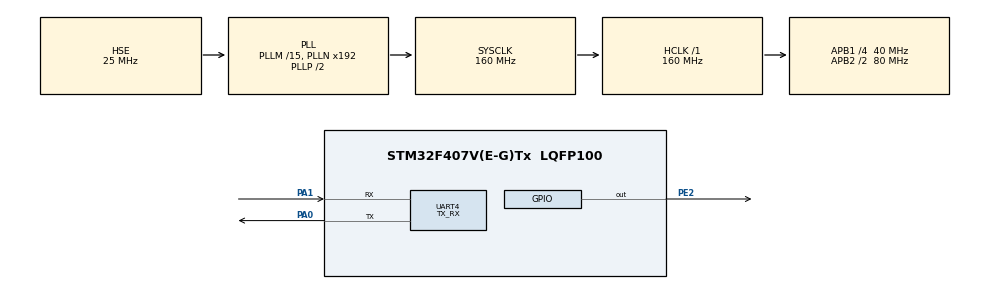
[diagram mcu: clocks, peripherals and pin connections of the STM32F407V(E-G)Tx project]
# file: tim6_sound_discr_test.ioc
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Dma.Request0=TIM6_UP
Dma.TIM6_UP.0.Direction=DMA_MEMORY_TO_PERIPH
Dma.TIM6_UP.0.FIFOMode=DMA_FIFOMODE_ENABLE
Dma.TIM6_UP.0.FIFOThreshold=DMA_FIFO_THRESHOLD_FULL
Dma.TIM6_UP.0.Instance=DMA1_Stream1
Dma.TIM6_UP.0.MemBurst=DMA_MBURST_SINGLE
Dma.TIM6_UP.0.MemDataAlignment=DMA_MDATAALIGN_HALFWORD
Dma.TIM6_UP.0.MemInc=DMA_MINC_ENABLE
Dma.TIM6_UP.0.Mode=DMA_NORMAL
Dma.TIM6_UP.0.PeriphBurst=DMA_PBURST_SINGLE
Dma.TIM6_UP.0.PeriphDataAlignment=DMA_PDATAALIGN_HALFWORD
Dma.TIM6_UP.0.PeriphInc=DMA_PINC_DISABLE
Dma.TIM6_UP.0.Priority=DMA_PRIORITY_LOW
Mcu.Family=STM32F4
Mcu.Name=STM32F407V(E-G)Tx
Mcu.Package=LQFP100
NVIC.DMA1_Stream1_IRQn=true\:0\:0\:false\:false\:true\:false\:true\:true
NVIC.PriorityGroup=NVIC_PRIORITYGROUP_4
NVIC.TIM6_DAC_IRQn=true\:0\:0\:false\:false\:true\:true\:true\:true
PA0-WKUP.Mode=Asynchronous
PA0-WKUP.Signal=UART4_TX
PA1.Mode=Asynchronous
PA1.Signal=UART4_RX
PA13.Mode=Serial_Wire
PA13.Signal=SYS_JTMS-SWDIO
PA14.Mode=Serial_Wire
PA14.Signal=SYS_JTCK-SWCLK
PE2.GPIO_PuPd=GPIO_PULLDOWN
PE2.GPIO_Speed=GPIO_SPEED_FREQ_LOW
PE2.PinState=GPIO_PIN_RESET
PE2.Signal=GPIO_Output
PH0-OSC_IN.Mode=HSE-External-Oscillator
PH0-OSC_IN.Signal=RCC_OSC_IN
PH1-OSC_OUT.Mode=HSE-External-Oscillator
PH1-OSC_OUT.Signal=RCC_OSC_OUT
ProjectManager.HeapSize=0x200
ProjectManager.StackSize=0x400
ProjectManager.TargetToolchain=STM32CubeIDE
RCC.48MHZClocksFreq_Value=80000000
RCC.AHBFreq_Value=160000000
RCC.APB1CLKDivider=RCC_HCLK_DIV4
RCC.APB1Freq_Value=40000000
RCC.APB1TimFreq_Value=80000000
RCC.APB2CLKDivider=RCC_HCLK_DIV2
RCC.APB2Freq_Value=80000000
RCC.APB2TimFreq_Value=160000000
RCC.CortexFreq_Value=160000000
RCC.HCLKFreq_Value=160000000
RCC.HSE_VALUE=25000000
RCC.HSI_VALUE=16000000
RCC.LSE_VALUE=32768
RCC.PLLM=15
RCC.PLLSourceVirtual=RCC_PLLSOURCE_HSE
RCC.SYSCLKFreq_VALUE=160000000
RCC.SYSCLKSource=RCC_SYSCLKSOURCE_PLLCLK
RCC.VCOOutputFreq_Value=320000000
TIM6.Period=1
TIM6.Prescaler=800
UART4.Mode=MODE_TX_RX
UART4.VirtualMode=Asynchronous
VP_TIM6_VS_ClockSourceINT.Mode=Enable_Timer
board=custom

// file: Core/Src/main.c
/* USER CODE BEGIN Header */
/**
  ******************************************************************************
  * @file           : main.c
  * @brief          : Main program body
  ******************************************************************************
  * @attention
  *
  * Copyright (c) 2024 STMicroelectronics.
  * All rights reserved.
  *
  * This software is licensed under terms that can be found in the LICENSE file
  * in the root directory of this software component.
  * If no LICENSE file comes with this software, it is provided AS-IS.
  *
  ******************************************************************************
  */
/* USER CODE END Header */
#include "main.h"

TIM_HandleTypeDef htim6;
DMA_HandleTypeDef hdma_tim6_up;

UART_HandleTypeDef huart4;

void SystemClock_Config(void);
static void MX_GPIO_Init(void);
static void MX_DMA_Init(void);
static void MX_TIM6_Init(void);
static void MX_UART4_Init(void);

int main(void)
{

  /* MCU Configuration--------------------------------------------------------*/

  /* Reset of all peripherals, Initializes the Flash interface and the Systick. */
  HAL_Init();

  /* Configure the system clock */
  SystemClock_Config();

  /* Initialize all configured peripherals */
  MX_GPIO_Init();
  MX_DMA_Init();
  MX_TIM6_Init();
  MX_UART4_Init();
  /* USER CODE BEGIN 2 */
  HAL_DMA_Init(&hdma_tim6_up);
  /* USER CODE END 2 */

  /* Infinite loop */
  while (1)
  {

  }
}

void SystemClock_Config(void)
{
  RCC_OscInitTypeDef RCC_OscInitStruct = {0};
  RCC_ClkInitTypeDef RCC_ClkInitStruct = {0};

  /** Configure the main internal regulator output voltage
  */
  __HAL_RCC_PWR_CLK_ENABLE();
  __HAL_PWR_VOLTAGESCALING_CONFIG(PWR_REGULATOR_VOLTAGE_SCALE1);

  /** Initializes the RCC Oscillators according to the specified parameters
  * in the RCC_OscInitTypeDef structure.
  */
  RCC_OscInitStruct.OscillatorType = RCC_OSCILLATORTYPE_HSE;
  RCC_OscInitStruct.HSEState = RCC_HSE_ON;
  RCC_OscInitStruct.PLL.PLLState = RCC_PLL_ON;
  RCC_OscInitStruct.PLL.PLLSource = RCC_PLLSOURCE_HSE;
  RCC_OscInitStruct.PLL.PLLM = 15;
  RCC_OscInitStruct.PLL.PLLN = 192;
  RCC_OscInitStruct.PLL.PLLP = RCC_PLLP_DIV2;
  RCC_OscInitStruct.PLL.PLLQ = 4;
  if (HAL_RCC_OscConfig(&RCC_OscInitStruct) != HAL_OK)
  {
    Error_Handler();
  }

  /** Initializes the CPU, AHB and APB buses clocks
  */
  RCC_ClkInitStruct.ClockType = RCC_CLOCKTYPE_HCLK|RCC_CLOCKTYPE_SYSCLK
                              |RCC_CLOCKTYPE_PCLK1|RCC_CLOCKTYPE_PCLK2;
  RCC_ClkInitStruct.SYSCLKSource = RCC_SYSCLKSOURCE_PLLCLK;
  RCC_ClkInitStruct.AHBCLKDivider = RCC_SYSCLK_DIV1;
  RCC_ClkInitStruct.APB1CLKDivider = RCC_HCLK_DIV4;
  RCC_ClkInitStruct.APB2CLKDivider = RCC_HCLK_DIV2;

  if (HAL_RCC_ClockConfig(&RCC_ClkInitStruct, FLASH_LATENCY_5) != HAL_OK)
  {
    Error_Handler();
  }
}

static void MX_TIM6_Init(void)
{

  TIM_MasterConfigTypeDef sMasterConfig = {0};

  htim6.Instance = TIM6;
  htim6.Init.Prescaler = 800;
  htim6.Init.CounterMode = TIM_COUNTERMODE_UP;
  htim6.Init.Period = 1;
  htim6.Init.AutoReloadPreload = TIM_AUTORELOAD_PRELOAD_DISABLE;
  if (HAL_TIM_Base_Init(&htim6) != HAL_OK)
  {
    Error_Handler();
  }
  sMasterConfig.MasterOutputTrigger = TIM_TRGO_RESET;
  sMasterConfig.MasterSlaveMode = TIM_MASTERSLAVEMODE_DISABLE;
  if (HAL_TIMEx_MasterConfigSynchronization(&htim6, &sMasterConfig) != HAL_OK)
  {
    Error_Handler();
  }

}

static void MX_UART4_Init(void)
{

  huart4.Instance = UART4;
  huart4.Init.BaudRate = 115200;
  huart4.Init.WordLength = UART_WORDLENGTH_8B;
  huart4.Init.StopBits = UART_STOPBITS_1;
  huart4.Init.Parity = UART_PARITY_NONE;
  huart4.Init.Mode = UART_MODE_TX_RX;
  huart4.Init.HwFlowCtl = UART_HWCONTROL_NONE;
  huart4.Init.OverSampling = UART_OVERSAMPLING_16;
  if (HAL_UART_Init(&huart4) != HAL_OK)
  {
    Error_Handler();
  }

}

static void MX_DMA_Init(void)
{

  /* DMA controller clock enable */
  __HAL_RCC_DMA1_CLK_ENABLE();

  /* DMA interrupt init */
  /* DMA1_Stream1_IRQn interrupt configuration */
  HAL_NVIC_SetPriority(DMA1_Stream1_IRQn, 0, 0);
  HAL_NVIC_EnableIRQ(DMA1_Stream1_IRQn);

}

static void MX_GPIO_Init(void)
{
  GPIO_InitTypeDef GPIO_InitStruct = {0};

  /* GPIO Ports Clock Enable */
  __HAL_RCC_GPIOE_CLK_ENABLE();
  __HAL_RCC_GPIOH_CLK_ENABLE();
  __HAL_RCC_GPIOA_CLK_ENABLE();

  /*Configure GPIO pin Output Level */
  HAL_GPIO_WritePin(GPIOE, GPIO_PIN_2, GPIO_PIN_RESET);

  /*Configure GPIO pin : PE2 */
  GPIO_InitStruct.Pin = GPIO_PIN_2;
  GPIO_InitStruct.Mode = GPIO_MODE_OUTPUT_PP;
  GPIO_InitStruct.Pull = GPIO_PULLDOWN;
  GPIO_InitStruct.Speed = GPIO_SPEED_FREQ_LOW;
  HAL_GPIO_Init(GPIOE, &GPIO_InitStruct);

}

void Error_Handler(void)
{
  __disable_irq();
  while (1)
  {
  }
}
